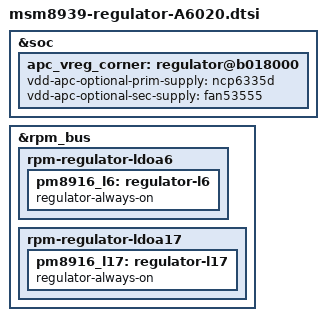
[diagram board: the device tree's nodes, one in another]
/* Copyright (c) 2014-2015, The Linux Foundation. All rights reserved.
 *
 * This program is free software; you can redistribute it and/or modify
 * it under the terms of the GNU General Public License version 2 and
 * only version 2 as published by the Free Software Foundation.
 *
 * This program is distributed in the hope that it will be useful,
 * but WITHOUT ANY WARRANTY; without even the implied warranty of
 * MERCHANTABILITY or FITNESS FOR A PARTICULAR PURPOSE.  See the
 * GNU General Public License for more details.
 */

/* Memory accelerator and CPR controlled regulators */

&soc {
	apc_vreg_corner: regulator@b018000 {
		vdd-apc-optional-prim-supply = <&ncp6335d>;
                vdd-apc-optional-sec-supply = <&fan53555>;
        };
};

/* RPM controlled regulators */

&rpm_bus {

	rpm-regulator-ldoa6 {
		pm8916_l6: regulator-l6 {
			regulator-always-on;
		};
	};

	rpm-regulator-ldoa17 {
		pm8916_l17: regulator-l17 {
			regulator-always-on;
		};
	};
};
